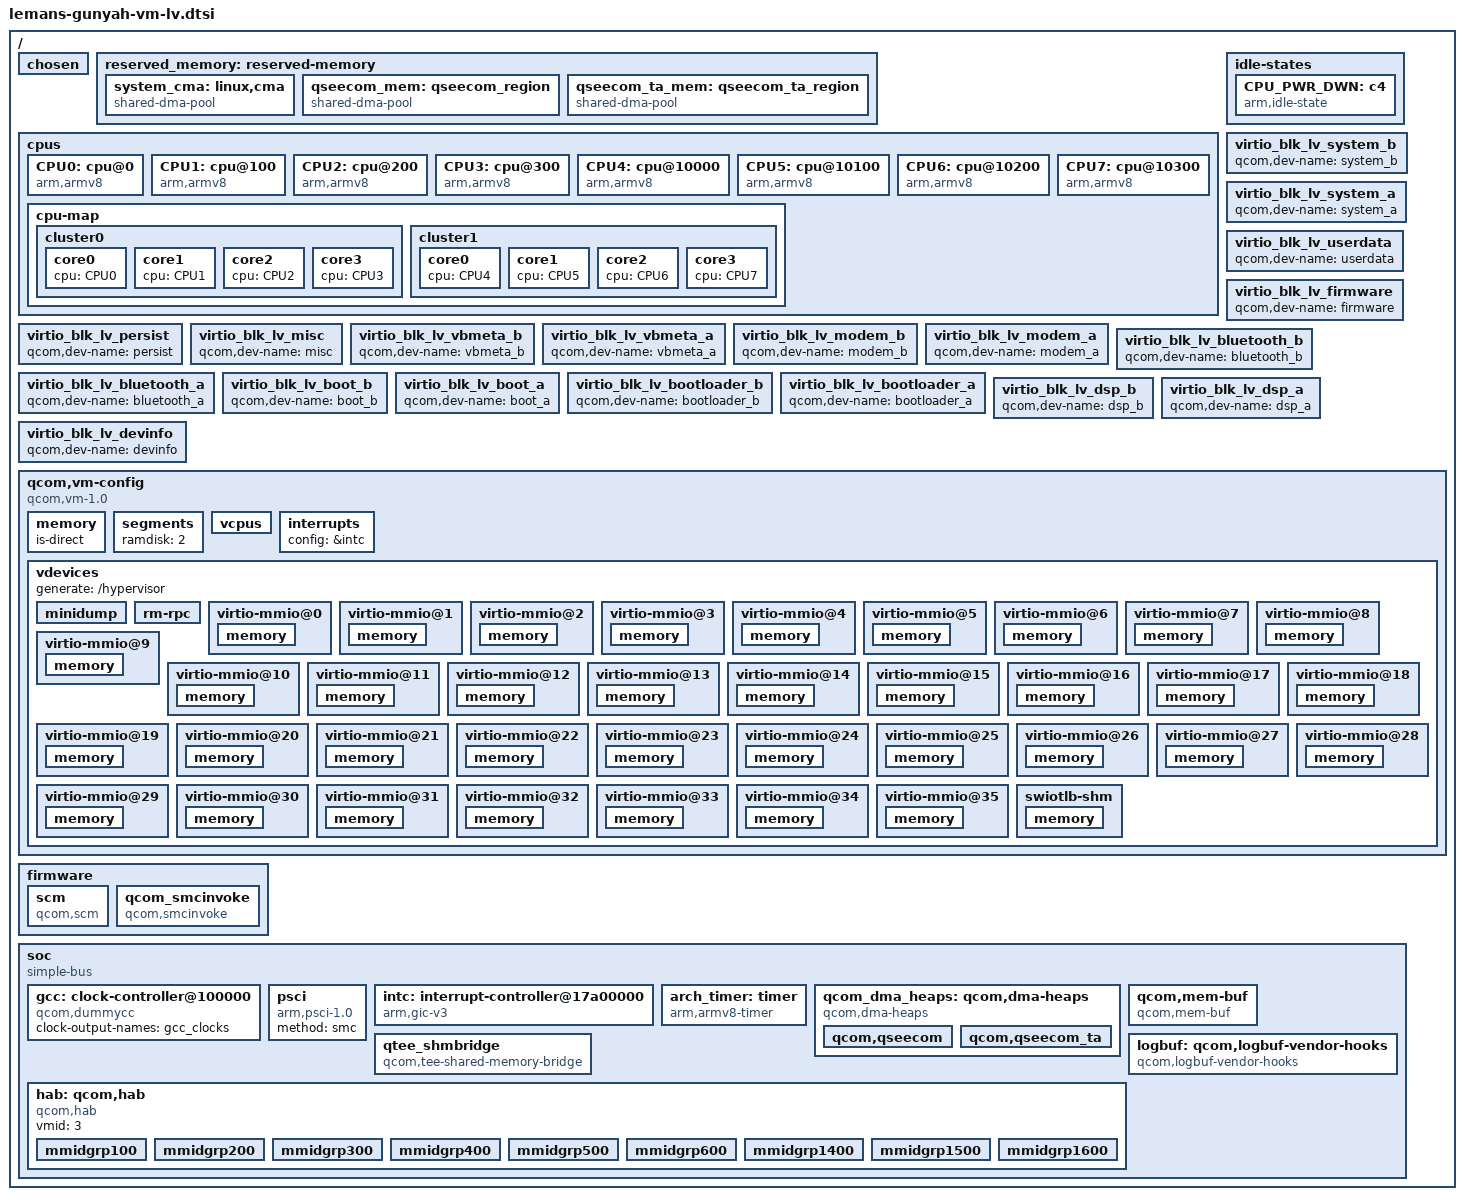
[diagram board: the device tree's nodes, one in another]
#include <dt-bindings/interrupt-controller/arm-gic.h>
#include <dt-bindings/arm/msm/qcom_dma_heap_dt_constants.h>

/ {
	#address-cells = <0x2>;
	#size-cells = <0x2>;
	qcom,msm-id = <532 0x10000>, <533 0x10000>, <534 0x10000>, <532 0x20000>, <533 0x20000>, <534 0x20000>;
	interrupt-parent = <&intc>;

	chosen {
		bootargs = "root=/dev/vda nokaslr log_buf_len=1M console=hvc0 loglevel=4 trace_event=scmi:* tp_printk trace_buf_size=4M";
	};

	reserved_memory: reserved-memory {
		#address-cells = <2>;
		#size-cells = <2>;
		ranges;

		system_cma: linux,cma {
			compatible = "shared-dma-pool";
			alloc-ranges = <0x0 0x0 0x0 0xffffffff>;
			reusable;
			alignment = <0x0 0x400000>;
			size = <0x0 0x2000000>;
			linux,cma-default;
		};

		qseecom_mem: qseecom_region {
			compatible = "shared-dma-pool";
			alloc-ranges = <0x0 0x00000000 0x0 0xffffffff>;
			reusable;
			alignment = <0x0 0x400000>;
			size = <0x0 0x1400000>;
		};

		qseecom_ta_mem: qseecom_ta_region {
			compatible = "shared-dma-pool";
			alloc-ranges = <0x0 0x00000000 0x0 0xffffffff>;
			reusable;
			alignment = <0x0 0x400000>;
			size = <0x0 0x1000000>;
		};
	};

	cpus {
		#address-cells = <0x2>;
		#size-cells = <0x0>;

		CPU0: cpu@0 {
			compatible = "arm,armv8";
			reg = <0x0 0x0>;
			device_type = "cpu";
			enable-method = "psci";
			cpu-idle-states = <&CPU_PWR_DWN>;
		};

		CPU1: cpu@100 {
			compatible = "arm,armv8";
			reg = <0x0 0x100>;
			device_type = "cpu";
			enable-method = "psci";
			cpu-idle-states = <&CPU_PWR_DWN>;
		};

		CPU2: cpu@200 {
			compatible = "arm,armv8";
			reg = <0x0 0x200>;
			device_type = "cpu";
			enable-method = "psci";
			cpu-idle-states = <&CPU_PWR_DWN>;
		};

		CPU3: cpu@300 {
			compatible = "arm,armv8";
			reg = <0x0 0x300>;
			device_type = "cpu";
			enable-method = "psci";
			cpu-idle-states = <&CPU_PWR_DWN>;
		};

		CPU4: cpu@10000 {
			compatible = "arm,armv8";
			reg = <0x0 0x10000>;
			device_type = "cpu";
			enable-method = "psci";
			cpu-idle-states = <&CPU_PWR_DWN>;
		};

		CPU5: cpu@10100 {
			compatible = "arm,armv8";
			reg = <0x0 0x10100>;
			device_type = "cpu";
			enable-method = "psci";
			cpu-idle-states = <&CPU_PWR_DWN>;
		};

		CPU6: cpu@10200 {
			compatible = "arm,armv8";
			reg = <0x0 0x10200>;
			device_type = "cpu";
			enable-method = "psci";
			cpu-idle-states = <&CPU_PWR_DWN>;
		};

		CPU7: cpu@10300 {
			compatible = "arm,armv8";
			reg = <0x0 0x10300>;
			device_type = "cpu";
			enable-method = "psci";
			cpu-idle-states = <&CPU_PWR_DWN>;
		};

		cpu-map {
			cluster0 {
				core0 {
					cpu = <&CPU0>;
				};

				core1 {
					cpu = <&CPU1>;
				};

				core2 {
					cpu = <&CPU2>;
				};

				core3 {
					cpu = <&CPU3>;
				};
			};

			cluster1 {
				core0 {
					cpu = <&CPU4>;
				};

				core1 {
					cpu = <&CPU5>;
				};

				core2 {
					cpu = <&CPU6>;
				};

				core3 {
					cpu = <&CPU7>;
				};
			};
		};
	};

	idle-states {
		CPU_PWR_DWN: c4 { /* C4 */
			compatible = "arm,idle-state";
			idle-state-name = "rail-pc";
			entry-latency-us = <702>;
			exit-latency-us = <1061>;
			min-residency-us = <4488>;
			arm,psci-suspend-param = <0x40000004>;
			local-timer-stop;
		};
	};

	virtio_blk_lv_system_b {
		qcom,dev-name = "system_b";
	};

	virtio_blk_lv_system_a {
		qcom,dev-name = "system_a";
	};

	virtio_blk_lv_userdata {
		qcom,dev-name = "userdata";
	};

	virtio_blk_lv_firmware {
		qcom,dev-name = "firmware";
	};

	virtio_blk_lv_persist {
		qcom,dev-name = "persist";
	};

	virtio_blk_lv_misc {
		qcom,dev-name = "misc";
	};

	virtio_blk_lv_vbmeta_b {
		qcom,dev-name = "vbmeta_b";
	};

	virtio_blk_lv_vbmeta_a {
		qcom,dev-name = "vbmeta_a";
	};

	virtio_blk_lv_modem_b {
		qcom,dev-name = "modem_b";
	};

	virtio_blk_lv_modem_a {
		qcom,dev-name = "modem_a";
	};

	virtio_blk_lv_bluetooth_b {
		qcom,dev-name = "bluetooth_b";
	};

	virtio_blk_lv_bluetooth_a {
		qcom,dev-name = "bluetooth_a";
	};

	virtio_blk_lv_boot_b {
		qcom,dev-name = "boot_b";
	};

	virtio_blk_lv_boot_a {
		qcom,dev-name = "boot_a";
	};

	virtio_blk_lv_bootloader_b {
		qcom,dev-name = "bootloader_b";
	};

	virtio_blk_lv_bootloader_a {
		qcom,dev-name = "bootloader_a";
	};

	virtio_blk_lv_dsp_b {
		qcom,dev-name = "dsp_b";
	};

	virtio_blk_lv_dsp_a {
		qcom,dev-name = "dsp_a";
	};

	virtio_blk_lv_devinfo {
		qcom,dev-name = "devinfo";
	};

	qcom,vm-config {
		compatible = "qcom,vm-1.0";
		vm-type = "aarch64-guest";
		boot-config = "fdt,unified";
		os-type = "linux";
		kernel-entry-segment = "kernel";
		kernel-entry-offset = <0x0 0x0>;
		vendor = "QTI";
		image-name = "qcom,autoghgvmlv";
		qcom,pasid = <0x0 0x2d>;
		qcom,qtee-config-info = "p=3,16,57,77,78,7A,7C,8F,97,159,199,47E,7F1,10C;";
		qcom,secdomain-ids = <53>;
		qcom,primary-vm-index = <0>;
		vm-attrs = "guest-ram-dump";

		memory {
			#address-cells = <0x2>;
			#size-cells = <0x0>;

			/* The IPA of the Guest regions is placed as IPA=PA */
			is-direct;
		};

		segments {
			ramdisk = <2>;
		};

		vcpus {
			config = "/cpus";
			affinity = "static";
			affinity-map = <0x7 0x6 0x5 0x4 0x3 0x2 0x1 0x0>;
			sched-priority = <0>;       /* relative to PVM */
			sched-timeslice = <5000>;   /* in us */
		};

		interrupts {
			config = &intc;
		};

		vdevices {
			generate = "/hypervisor";
			minidump {
				vdevice-type = "minidump";
				push-compatible = "qcom,minidump_rm";
				minidump_allowed;
			};

			rm-rpc {
				vdevice-type = "rm-rpc";
				generate = "/hypervisor/qcom,resource-mgr";
				console-dev;
				message-size = <0x000000f0>;
				queue-depth = <0x00000008>;
				qcom,label = <0x1>;
			};

			virtio-mmio@0 {
				vdevice-type = "virtio-mmio";
				generate = "/virtio-mmio";
				peer-default;
				vqs-num = <0x1>;
				push-compatible = "virtio,mmio";
				sync-reset;
				dma-coherent;
				dma_base = <0x0 0x0>;
				memory {
					qcom,label = <0x100>;
					#address-cells = <0x2>;
					allocate-base;
				};
			};

			virtio-mmio@1 {
				vdevice-type = "virtio-mmio";
				patch = "/virtio_blk_lv_devinfo";
				peer-default;
				vqs-num = <0x1>;
				push-compatible = "virtio,mmio";
				sync-reset;
				dma-coherent;
				dma_base = <0x0 0x4000>;
				memory {
					qcom,label = <0x101>;
					#address-cells = <0x2>;
					allocate-base;
				};
			};

			virtio-mmio@2 {
				vdevice-type = "virtio-mmio";
				patch = "/virtio_blk_lv_dsp_a";
				peer-default;
				vqs-num = <0x1>;
				push-compatible = "virtio,mmio";
				sync-reset;
				dma-coherent;
				dma_base = <0x0 0x8000>;
				memory {
					qcom,label = <0x102>;
					#address-cells = <0x2>;
					allocate-base;
				};
			};

			virtio-mmio@3 {
				vdevice-type = "virtio-mmio";
				patch = "/virtio_blk_lv_dsp_b";
				peer-default;
				vqs-num = <0x1>;
				push-compatible = "virtio,mmio";
				sync-reset;
				dma-coherent;
				dma_base = <0x0 0xC000>;
				memory {
					qcom,label = <0x103>;
					#address-cells = <0x2>;
					allocate-base;
				};
			};

			virtio-mmio@4 {
				vdevice-type = "virtio-mmio";
				patch = "/virtio_blk_lv_bootloader_a";
				peer-default;
				vqs-num = <0x1>;
				push-compatible = "virtio,mmio";
				sync-reset;
				dma-coherent;
				dma_base = <0x0 0x10000>;
				memory {
					qcom,label = <0x104>;
					#address-cells = <0x2>;
					allocate-base;
				};
			};

			virtio-mmio@5 {
				vdevice-type = "virtio-mmio";
				patch = "/virtio_blk_lv_bootloader_b";
				peer-default;
				vqs-num = <0x1>;
				push-compatible = "virtio,mmio";
				sync-reset;
				dma-coherent;
				dma_base = <0x0 0x14000>;
				memory {
					qcom,label = <0x105>;
					#address-cells = <0x2>;
					allocate-base;
				};
			};

			virtio-mmio@6 {
				vdevice-type = "virtio-mmio";
				patch = "/virtio_blk_lv_boot_a";
				peer-default;
				vqs-num = <0x1>;
				push-compatible = "virtio,mmio";
				sync-reset;
				dma-coherent;
				dma_base = <0x0 0x18000>;
				memory {
					qcom,label = <0x106>;
					#address-cells = <0x2>;
					allocate-base;
				};
			};

			virtio-mmio@7 {
				vdevice-type = "virtio-mmio";
				patch = "/virtio_blk_lv_boot_b";
				peer-default;
				vqs-num = <0x1>;
				push-compatible = "virtio,mmio";
				sync-reset;
				dma-coherent;
				dma_base = <0x0 0x1C000>;
				memory {
					qcom,label = <0x107>;
					#address-cells = <0x2>;
					allocate-base;
				};
			};

			virtio-mmio@8 {
				vdevice-type = "virtio-mmio";
				patch = "/virtio_blk_lv_bluetooth_a";
				peer-default;
				vqs-num = <0x1>;
				push-compatible = "virtio,mmio";
				sync-reset;
				dma-coherent;
				dma_base = <0x0 0x20000>;
				memory {
					qcom,label = <0x108>;
					#address-cells = <0x2>;
					allocate-base;
				};
			};

			virtio-mmio@9 {
				vdevice-type = "virtio-mmio";
				patch = "/virtio_blk_lv_bluetooth_b";
				peer-default;
				vqs-num = <0x1>;
				push-compatible = "virtio,mmio";
				sync-reset;
				dma-coherent;
				dma_base = <0x0 0x24000>;
				memory {
					qcom,label = <0x109>;
					#address-cells = <0x2>;
					allocate-base;
				};
			};

			virtio-mmio@10 {
				vdevice-type = "virtio-mmio";
				patch = "/virtio_blk_lv_modem_a";
				peer-default;
				vqs-num = <0x1>;
				push-compatible = "virtio,mmio";
				sync-reset;
				dma-coherent;
				dma_base = <0x0 0x28000>;
				memory {
					qcom,label = <0x10A>;
					#address-cells = <0x2>;
					allocate-base;
				};
			};

			virtio-mmio@11 {
				vdevice-type = "virtio-mmio";
				patch = "/virtio_blk_lv_modem_b";
				peer-default;
				vqs-num = <0x1>;
				push-compatible = "virtio,mmio";
				sync-reset;
				dma-coherent;
				dma_base = <0x0 0x2C000>;
				memory {
					qcom,label = <0x10B>;
					#address-cells = <0x2>;
					allocate-base;
				};
			};

			virtio-mmio@12 {
				vdevice-type = "virtio-mmio";
				patch = "/virtio_blk_lv_vbmeta_a";
				peer-default;
				vqs-num = <0x1>;
				push-compatible = "virtio,mmio";
				sync-reset;
				dma-coherent;
				dma_base = <0x0 0x30000>;
				memory {
					qcom,label = <0x10C>;
					#address-cells = <0x2>;
					allocate-base;
				};
			};

			virtio-mmio@13 {
				vdevice-type = "virtio-mmio";
				patch = "/virtio_blk_lv_vbmeta_b";
				peer-default;
				vqs-num = <0x1>;
				push-compatible = "virtio,mmio";
				sync-reset;
				dma-coherent;
				dma_base = <0x0 0x34000>;
				memory {
					qcom,label = <0x10D>;
					#address-cells = <0x2>;
					allocate-base;
				};
			};

			virtio-mmio@14 {
				vdevice-type = "virtio-mmio";
				patch = "/virtio_blk_lv_misc";
				peer-default;
				vqs-num = <0x1>;
				push-compatible = "virtio,mmio";
				sync-reset;
				dma-coherent;
				dma_base = <0x0 0x38000>;
				memory {
					qcom,label = <0x10E>;
					#address-cells = <0x2>;
					allocate-base;
				};
			};

			virtio-mmio@15 {
				vdevice-type = "virtio-mmio";
				patch = "/virtio_blk_lv_persist";
				peer-default;
				vqs-num = <0x1>;
				push-compatible = "virtio,mmio";
				sync-reset;
				dma-coherent;
				dma_base = <0x0 0x3C000>;
				memory {
					qcom,label = <0x10F>;
					#address-cells = <0x2>;
					allocate-base;
				};
			};

			virtio-mmio@16 {
				vdevice-type = "virtio-mmio";
				patch = "/virtio_blk_lv_firmware";
				peer-default;
				vqs-num = <0x1>;
				push-compatible = "virtio,mmio";
				sync-reset;
				dma-coherent;
				dma_base = <0x0 0x40000>;
				memory {
					qcom,label = <0x110>;
					#address-cells = <0x2>;
					allocate-base;
				};
			};

			virtio-mmio@17 {
				vdevice-type = "virtio-mmio";
				patch = "/virtio_blk_lv_userdata";
				peer-default;
				vqs-num = <0x1>;
				push-compatible = "virtio,mmio";
				sync-reset;
				dma-coherent;
				dma_base = <0x0 0x44000>;
				memory {
					qcom,label = <0x111>;
					#address-cells = <0x2>;
					allocate-base;
				};
			};

			virtio-mmio@18 {
				vdevice-type = "virtio-mmio";
				patch = "/virtio_blk_lv_system_a";
				peer-default;
				vqs-num = <0x1>;
				push-compatible = "virtio,mmio";
				sync-reset;
				dma-coherent;
				dma_base = <0x0 0x48000>;
				memory {
					qcom,label = <0x112>;
					#address-cells = <0x2>;
					allocate-base;
				};
			};

			virtio-mmio@19 {
				vdevice-type = "virtio-mmio";
				patch = "/virtio_blk_lv_system_b";
				peer-default;
				vqs-num = <0x1>;
				push-compatible = "virtio,mmio";
				sync-reset;
				dma-coherent;
				dma_base = <0x0 0x4C000>;
				memory {
					qcom,label = <0x113>;
					#address-cells = <0x2>;
					allocate-base;
				};
			};

			virtio-mmio@20 {
				vdevice-type = "virtio-mmio";
				generate = "/virtio-mmio";
				peer-default;
				vqs-num = <0x2>;
				push-compatible = "virtio,mmio";
				sync-reset;
				dma-coherent;
				dma_base = <0x0 0x50000>;
				memory {
					qcom,label = <0x114>;
					#address-cells = <0x2>;
					allocate-base;
				};
			};

			virtio-mmio@21 {
				vdevice-type = "virtio-mmio";
				generate = "/virtio-mmio";
				peer-default;
				vqs-num = <0x2>;
				push-compatible = "virtio,mmio";
				sync-reset;
				dma-coherent;
				dma_base = <0x0 0x58000>;
				memory {
					qcom,label = <0x115>;
					#address-cells = <0x2>;
					allocate-base;
				};
			};

			/*hab 0*/
			virtio-mmio@22 {
				vdevice-type = "virtio-mmio";
				generate = "/virtio-mmio";
				peer-default;
				vqs-num = <0x2>;
				push-compatible = "virtio,mmio";
				sync-reset;
				dma-coherent;
				dma_base = <0x0 0x60000>;
				memory {
					qcom,label = <0x116>;
					#address-cells = <0x2>;
					allocate-base;
				};
			};

			/*hab 1*/
			virtio-mmio@23 {
				vdevice-type = "virtio-mmio";
				generate = "/virtio-mmio";
				peer-default;
				vqs-num = <0x2>;
				push-compatible = "virtio,mmio";
				sync-reset;
				dma-coherent;
				dma_base = <0x0 0x70000>;
				memory {
					qcom,label = <0x117>;
					#address-cells = <0x2>;
					allocate-base;
				};
			};

			/*hab 2*/
			virtio-mmio@24 {
				vdevice-type = "virtio-mmio";
				generate = "/virtio-mmio";
				peer-default;
				vqs-num = <0x8>;
				push-compatible = "virtio,mmio";
				sync-reset;
				dma-coherent;
				dma_base = <0x0 0x80000>;
				memory {
					qcom,label = <0x118>;
					#address-cells = <0x2>;
					allocate-base;
				};
			};

			/*hab 3*/
			virtio-mmio@25 {
				vdevice-type = "virtio-mmio";
				generate = "/virtio-mmio";
				peer-default;
				vqs-num = <0xA>;
				push-compatible = "virtio,mmio";
				sync-reset;
				dma-coherent;
				dma_base = <0x0 0xC0000>;
				memory {
					qcom,label = <0x119>;
					#address-cells = <0x2>;
					allocate-base;
				};
			};

			/*hab 4*/
			virtio-mmio@26 {
				vdevice-type = "virtio-mmio";
				generate = "/virtio-mmio";
				peer-default;
				vqs-num = <0x6>;
				push-compatible = "virtio,mmio";
				sync-reset;
				dma-coherent;
				dma_base = <0x0 0x110000>;
				memory {
					qcom,label = <0x11A>;
					#address-cells = <0x2>;
					allocate-base;
				};
			};

			/*hab 5*/
			virtio-mmio@27 {
				vdevice-type = "virtio-mmio";
				generate = "/virtio-mmio";
				peer-default;
				vqs-num = <0x6>;
				push-compatible = "virtio,mmio";
				sync-reset;
				dma-coherent;
				dma_base = <0x0 0x140000>;
				memory {
					qcom,label = <0x11B>;
					#address-cells = <0x2>;
					allocate-base;
				};
			};

			/*hab 6*/
			virtio-mmio@28 {
				vdevice-type = "virtio-mmio";
				generate = "/virtio-mmio";
				peer-default;
				vqs-num = <0x2>;
				push-compatible = "virtio,mmio";
				sync-reset;
				dma-coherent;
				dma_base = <0x0 0x170000>;
				memory {
					qcom,label = <0x11C>;
					#address-cells = <0x2>;
					allocate-base;
				};
			};

			/*hab 7*/
			virtio-mmio@29 {
				vdevice-type = "virtio-mmio";
				generate = "/virtio-mmio";
				peer-default;
				vqs-num = <0x2>;
				push-compatible = "virtio,mmio";
				sync-reset;
				dma-coherent;
				dma_base = <0x0 0x180000>;
				memory {
					qcom,label = <0x11D>;
					#address-cells = <0x2>;
					allocate-base;
				};
			};

			/*hab 8*/
			virtio-mmio@30 {
				vdevice-type = "virtio-mmio";
				generate = "/virtio-mmio";
				peer-default;
				vqs-num = <0x6>;
				push-compatible = "virtio,mmio";
				sync-reset;
				dma-coherent;
				dma_base = <0x0 0x190000>;
				memory {
					qcom,label = <0x11E>;
					#address-cells = <0x2>;
					allocate-base;
				};
			};

			virtio-mmio@31 {
				vdevice-type = "virtio-mmio";
				generate = "/virtio-mmio";
				peer-default;
				vqs-num = <0x2>;
				push-compatible = "virtio,mmio";
				sync-reset;
				dma-coherent;
				dma_base = <0x0 0x1C0000>;
				memory {
					qcom,label = <0x11F>;
					#address-cells = <0x2>;
					allocate-base;
				};
			};

			virtio-mmio@32 {
				vdevice-type = "virtio-mmio";
				generate = "/virtio-mmio";
				peer-default;
				vqs-num = <0x2>;
				push-compatible = "virtio,mmio";
				sync-reset;
				dma-coherent;
				dma_base = <0x0 0x1C4000>;
				memory {
					qcom,label = <0x120>;
					#address-cells = <0x2>;
					allocate-base;
				};
			};

			virtio-mmio@33 {
				vdevice-type = "virtio-mmio";
				generate = "/virtio-mmio";
				peer-default;
				vqs-num = <0x2>;
				push-compatible = "virtio,mmio";
				sync-reset;
				dma-coherent;
				dma_base = <0x0 0x1C8000>;
				memory {
					qcom,label = <0x121>;
					#address-cells = <0x2>;
					allocate-base;
				};
			};

			/*i2c 0*/
			virtio-mmio@34 {
				vdevice-type = "virtio-mmio";
				generate = "/virtio-mmio";
				peer-default;
				vqs-num = <0x1>;
				push-compatible = "virtio,mmio";
				sync-reset;
				dma-coherent;
				dma_base = <0x0 0x1CC000>;
				memory {
					qcom,label = <0x122>;
					#address-cells = <0x2>;
					allocate-base;
				};
			};

			virtio-mmio@35 {
				vdevice-type = "virtio-mmio";
				generate = "/virtio-mmio";
				peer-default;
				vqs-num = <0x2>;
				push-compatible = "virtio,mmio";
				sync-reset;
				dma-coherent;
				dma_base = <0x0 0x1CE000>;
				memory {
					qcom,label = <0x123>;
					#address-cells = <0x2>;
					allocate-base;
				};
			};

			swiotlb-shm {
				vdevice-type = "shm";
				generate = "/swiotlb";
				push-compatible = "swiotlb";
				peer-default;
				dma_base = <0x0 0x1100000>;
				memory {
					qcom,label = <0x140>;
					#address-cells = <0x2>;
					allocate-base;
				};
			};
		};
	};

	firmware: firmware {
		scm {
			compatible = "qcom,scm";
		};

		qcom_smcinvoke {
			compatible = "qcom,smcinvoke";
		};
	};

	soc: soc { };
};

&soc {
	#address-cells = <1>;
	#size-cells = <1>;
	ranges = <0 0 0 0xffffffff>;
	compatible = "simple-bus";

	gcc: clock-controller@100000 {
		compatible = "qcom,dummycc";
		clock-output-names = "gcc_clocks";
		#clock-cells = <1>;
		#reset-cells = <1>;
	};

	psci {
		compatible = "arm,psci-1.0";
		method = "smc";
	};

	intc: interrupt-controller@17a00000 {
		compatible = "arm,gic-v3";
		interrupt-controller;
		#interrupt-cells = <0x3>;
		#redistributor-regions = <1>;
		redistributor-stride = <0x0 0x20000>;
		reg = <0x17a00000 0x10000>,     /* GICD */
		      <0x17a60000 0x100000>;    /* GICR * 8 */
	};

	arch_timer: timer {
		compatible = "arm,armv8-timer";
		always-on;
		interrupts = <GIC_PPI 13 (GIC_CPU_MASK_SIMPLE(8) | IRQ_TYPE_LEVEL_LOW)>,
			     <GIC_PPI 14 (GIC_CPU_MASK_SIMPLE(8) | IRQ_TYPE_LEVEL_LOW)>,
			     <GIC_PPI 11 (GIC_CPU_MASK_SIMPLE(8) | IRQ_TYPE_LEVEL_LOW)>,
			     <GIC_PPI 12 (GIC_CPU_MASK_SIMPLE(8) | IRQ_TYPE_LEVEL_LOW)>;
		clock-frequency = <19200000>;
	};

	qcom_dma_heaps: qcom,dma-heaps {
		compatible = "qcom,dma-heaps";

		qcom,qseecom {
			qcom,dma-heap-name = "qcom,qseecom";
			qcom,dma-heap-type = <HEAP_TYPE_CMA>;
			memory-region = <&qseecom_mem>;
		};

		qcom,qseecom_ta {
			qcom,dma-heap-name = "qcom,qseecom-ta";
			qcom,dma-heap-type = <HEAP_TYPE_CMA>;
			memory-region = <&qseecom_ta_mem>;
		};
	};

	qcom,mem-buf {
		compatible = "qcom,mem-buf";
		qcom,mem-buf-capabilities = "consumer";
		qcom,vmid = <53>;
	};

	qtee_shmbridge {
		compatible = "qcom,tee-shared-memory-bridge";
		qcom,custom-bridge-size = <512>;
		qcom,support-hypervisor;
	};

	logbuf: qcom,logbuf-vendor-hooks {
		compatible = "qcom,logbuf-vendor-hooks";
	};
};

&soc {
	hab: qcom,hab {
		compatible = "qcom,hab";
		vmid = <3>;

		mmidgrp100: mmidgrp100 {
			grp-start-id = <100>;
			role = "fe";
			remote-vmids = <0>;
		};

		mmidgrp200: mmidgrp200 {
			grp-start-id = <200>;
			role = "fe";
			remote-vmids = <0>;
		};

		mmidgrp300: mmidgrp300 {
			grp-start-id = <300>;
			role = "fe";
			remote-vmids = <0>;
		};

		mmidgrp400: mmidgrp400 {
			grp-start-id = <400>;
			role = "fe";
			remote-vmids = <0>;
		};

		mmidgrp500: mmidgrp500 {
			grp-start-id = <500>;
			role = "fe";
			remote-vmids = <0>;
		};

		mmidgrp600: mmidgrp600 {
			grp-start-id = <600>;
			role = "fe";
			remote-vmids = <0>;
		};

		mmidgrp1400: mmidgrp1400 {
			grp-start-id = <1400>;
			role = "fe";
			remote-vmids = <0>;
		};

		mmidgrp1500: mmidgrp1500 {
			grp-start-id = <1500>;
			role = "fe";
			remote-vmids = <0>;
		};

		mmidgrp1600: mmidgrp1600 {
			grp-start-id = <1600>;
			role = "fe";
			remote-vmids = <0>;
		};
	};
};
